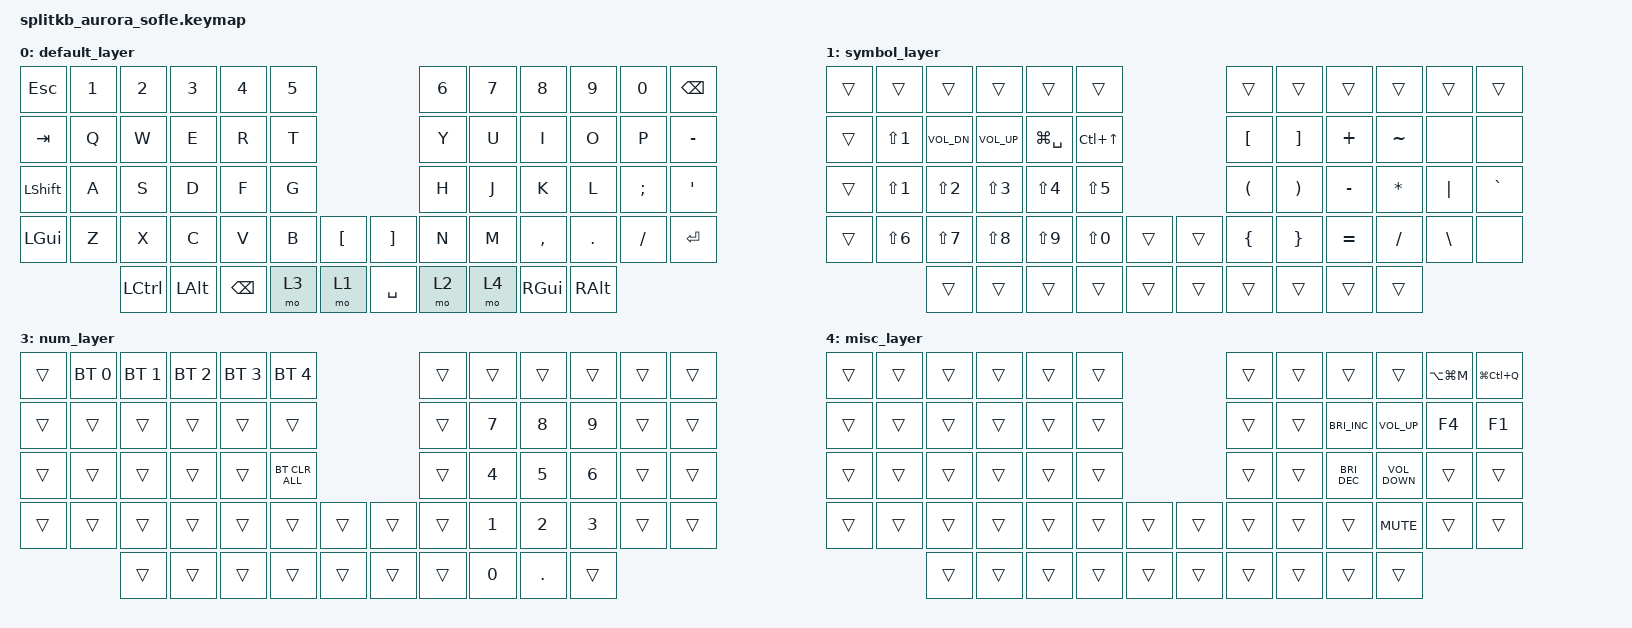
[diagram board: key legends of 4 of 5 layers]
/*
 * Copyright (c) 2023 The ZMK Contributors
 *
 * SPDX-License-Identifier: MIT
 */

#include <behaviors.dtsi>
#include <dt-bindings/zmk/bt.h>
#include <dt-bindings/zmk/keys.h>

#define AS(keycode) &as LS(keycode) keycode     // Autoshift Macro

/* Uncomment this block if using RGB
&led_strip {
    chain-length = <6>;
    // chain-length = <35>; // Uncomment if using both per-key and underglow LEDs
    // chain-length = <29>; // Uncomment if using only per-key LEDs.
};
 */

/ {
    behaviors {
        as: auto_shift {
            compatible = "zmk,behavior-hold-tap";
            label = "AUTO_SHIFT";
            #binding-cells = <2>;
            tapping_term_ms = <210>;
            quick_tap_ms = <0>;
            flavor = "tap-preferred";
            bindings = <&kp>, <&kp>;
        };

        mo_to: mo_to {
            compatible = "zmk,behavior-tap-dance";
            label = "MO_TO";
            #binding-cells = <0>;
            bindings = <&mo 3>, <&mo 4>;
        };
    };
};

/ {
    keymap {
        compatible = "zmk,keymap";

        default_layer {
            // ------------------------------------------------------------------------------------------------------------
            // |  ESC  |  1  |  2  |  3   |  4   |  5   |                   |  6   |  7    |  8    |  9   |   0   | Backspc|
            // |  TAB  |  Q  |  W  |  E   |  R   |  T   |                   |  Y   |  U    |  I    |  O   |   P   |   -   |
            // |  CTRL |  A  |  S  |  D   |  F   |  G   |                   |  H   |  J    |  K    |  L   |   ;   |   '   |
            // | SHIFT |  Z  |  X  |  C   |  V   |  B   |   "["  |  |  "]"  |  N   |  M    |  ,    |  .   |   /   | Return |
            //               |CTRL | ALT  | GUI  | LOWER|  SPACE |  | ENTER | RAISE| BSPC  | GUI   | RALT |

            bindings = <
&kp ESC       &kp N1  &kp N2            &kp N3        &kp N4    &kp N5                         &kp N6  &kp N7  &kp N8     &kp N9    &kp N0    &kp BSPC
&kp TAB       &kp Q   &kp W             &kp E         &kp R     &kp T                          &kp Y   &kp U   &kp I      &kp O     &kp P     &kp MINUS
&kp LSHFT     &kp A   &kp S             &kp D         &kp F     &kp G                          &kp H   &kp J   &kp K      &kp L     &kp SEMI  &kp SQT
&kp LEFT_GUI  &kp Z   &kp X             &kp C         &kp V     &kp B   &kp LBKT    &kp RBKT   &kp N   &kp M   &kp COMMA  &kp DOT   &kp FSLH  &kp RET
                      &kp LEFT_CONTROL  &kp LEFT_ALT  &kp BSPC  &mo 3   &mo 1       &kp SPACE  &mo 2   &mo 4   &kp RGUI   &kp RALT
            >;

            sensor-bindings = <&inc_dec_kp C_VOL_UP C_VOL_DN>;
        };

        symbol_layer {
            // ------------------------------------------------------------------------------------------------------------
            // | BTCLR | BT1 | BT2 |  BT3 |  BT4 |  BT5 |                   |      |       |       |      |       |       |
            // |  F1   |  F2 |  F3 |  F4  |  F5  |  F6  |                   |  [   |  ]    |  +    |  ~   |  F11  |  F12  |
            // |   `   |  !  |  @  |  #   |  $   |  %   |                   |  (   |  )    |  -    |  *   |   "|" |   `   |
            // |       |  ^  |  &  |  *   |  (   |  )   |        |  |       |  {   |  }    |  =    |  /   |    \  |empty  |
            //               |     |      |      |      |        |  |       |      |       |       |      |

            bindings = <
&trans  &trans      &trans        &trans        &trans         &trans                        &trans    &trans    &trans     &trans        &trans    &trans
&trans  &kp LS(N1)  &kp C_VOL_DN  &kp C_VOL_UP  &kp LG(SPACE)  &kp LC(UP)                    &kp LBKT  &kp RBKT  &kp PLUS   &kp TILDE     &none     &none
&trans  &kp LS(N1)  &kp LS(N2)    &kp LS(N3)    &kp LS(N4)     &kp LS(N5)                    &kp LPAR  &kp RPAR  &kp MINUS  &kp ASTERISK  &kp PIPE  &kp GRAVE
&trans  &kp LS(N6)  &kp LS(N7)    &kp LS(N8)    &kp LS(N9)     &kp LS(N0)  &trans    &trans  &kp LBRC  &kp RBRC  &kp EQUAL  &kp FSLH      &kp BSLH  &none
                    &trans        &trans        &trans         &trans      &trans    &trans  &trans    &trans    &trans     &trans
            >;

            sensor-bindings = <&inc_dec_kp C_VOL_UP C_VOL_DN>;
        };

        navigation_layer {
            // ------------------------------------------------------------------------------------------------------------
            // |       |     |     |      |      |      |                   |      |       |       |      |       |       |
            // |   `   |  1  |  2  |  3   |  4   |  5   |                   |  6   |   7   |   8   |  9   |   0   |       |
            // |   F1  |  F2 |  F3 |  F4  |  F5  |  F6  |                   |      |   <-  |   v   |  ^   |  ->   |       |
            // |   F7  |  F8 |  F9 |  F10 |  F11 |  F12 |        |  |       |  +   |   -   |   =   |  [   |   ]   |   \   |
            //               |     |      |      |      |        |  |       |      |       |       |      |

            bindings = <
&trans  &kp F1  &kp F2        &kp F3  &kp F4  &kp F5                        &kp F6  &kp F7     &kp F8     &kp F9     &kp F10  &kp F11
&trans  &trans  &trans        &trans  &trans  &trans                        &trans  &kp PG_DN  &kp PG_UP  &kp DEL    &trans   &kp F1
&trans  &trans  &trans        &trans  &trans  &bt BT_CLR                    &trans  &kp HOME   &kp UP     &kp END    &kp INS  &kp F7
&trans  &trans  &trans        &trans  &trans  &trans      &trans    &trans  &trans  &kp LEFT   &kp DOWN   &kp RIGHT  &trans   &trans
                &kp CAPSLOCK  &trans  &trans  &trans      &trans    &trans  &trans  &trans     &trans
            >;

            sensor-bindings = <&inc_dec_kp C_VOL_UP C_VOL_DN>;
        };

        num_layer {
            // ------------------------------------------------------------------------------------------------------------
            // |       |     |     |      |      |      |                   |      |       |       |      |       |       |
            // |   `   |  1  |  2  |  3   |  4   |  5   |                   |  6   |   7   |   8   |  9   |   0   |       |
            // |   F1  |  F2 |  F3 |  F4  |  F5  |  F6  |                   |      |   <-  |   v   |  ^   |  ->   |       |
            // |   F7  |  F8 |  F9 |  F10 |  F11 |  F12 |        |  |       |  +   |   -   |   =   |  [   |   ]   |   \   |
            //               |     |      |      |      |        |  |       |      |       |       |      |

            bindings = <
&trans  &bt BT_SEL 0  &bt BT_SEL 1  &bt BT_SEL 2  &bt BT_SEL 3  &bt BT_SEL 4                      &trans  &trans  &trans   &trans  &trans  &trans
&trans  &trans        &trans        &trans        &trans        &trans                            &trans  &kp N7  &kp N8   &kp N9  &trans  &trans
&trans  &trans        &trans        &trans        &trans        &bt BT_CLR_ALL                    &trans  &kp N4  &kp N5   &kp N6  &trans  &trans
&trans  &trans        &trans        &trans        &trans        &trans          &trans    &trans  &trans  &kp N1  &kp N2   &kp N3  &trans  &trans
                      &trans        &trans        &trans        &trans          &trans    &trans  &trans  &kp N0  &kp DOT  &trans
            >;

            sensor-bindings = <&inc_dec_kp C_VOL_UP C_VOL_DN>;
        };

        misc_layer {
            // ------------------------------------------------------------------------------------------------------------
            // |       |     |     |      |      |      |                   |      |       |       |      |ctrlaltentf   |SLEEP  |
            // |   `   |  1  |  2  |  3   |  4   |  5   |                   |  6   |   7   |brighte|lauter|   F4   |   F12    |
            // |   F1  |  F2 |  F3 |  F4  |  F5  |  F6  |                   |      |   <-  |dimmer |leiser|  ->   |       |
            // |   F7  |  F8 |  F9 |  F10 |  F11 |  F12 |        |  |       |  +   |   -   |   =   |  mute|   ]   |   \   |
            //               |     |      |      |      |        |  |       |      |       |       |      |

            bindings = <
&trans  &trans  &trans  &trans  &trans  &trans                    &trans  &trans  &trans                &trans             &kp LA(LG(M))  &kp LG(LC(Q))
&trans  &trans  &trans  &trans  &trans  &trans                    &trans  &trans  &kp C_BRIGHTNESS_INC  &kp C_VOLUME_UP    &kp F4         &kp F1
&trans  &trans  &trans  &trans  &trans  &trans                    &trans  &trans  &kp C_BRIGHTNESS_DEC  &kp C_VOLUME_DOWN  &trans         &trans
&trans  &trans  &trans  &trans  &trans  &trans  &trans    &trans  &trans  &trans  &trans                &kp C_MUTE         &trans         &trans
                &trans  &trans  &trans  &trans  &trans    &trans  &trans  &trans  &trans                &trans
            >;

            sensor-bindings = <&inc_dec_kp C_VOL_UP C_VOL_DN>;
        };
    };
};
